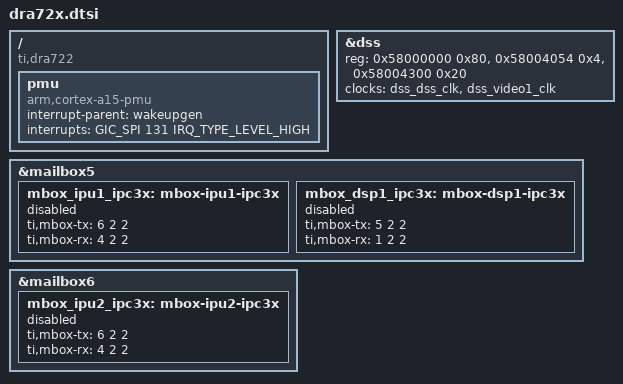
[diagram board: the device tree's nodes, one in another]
// SPDX-License-Identifier: GPL-2.0-only
/*
 * Copyright (C) 2014 Texas Instruments Incorporated - https://www.ti.com/
 *
 * Based on "omap4.dtsi"
 */

#include "dra7.dtsi"

/ {
	compatible = "ti,dra722", "ti,dra72", "ti,dra7";

	pmu {
		compatible = "arm,cortex-a15-pmu";
		interrupt-parent = <&wakeupgen>;
		interrupts = <GIC_SPI 131 IRQ_TYPE_LEVEL_HIGH>;
	};
};

&dss {
	reg = <0x58000000 0x80>,
	      <0x58004054 0x4>,
	      <0x58004300 0x20>;
	reg-names = "dss", "pll1_clkctrl", "pll1";

	clocks = <&dss_dss_clk>,
		 <&dss_video1_clk>;
	clock-names = "fck", "video1_clk";
};

&mailbox5 {
	mbox_ipu1_ipc3x: mbox-ipu1-ipc3x {
		ti,mbox-tx = <6 2 2>;
		ti,mbox-rx = <4 2 2>;
		status = "disabled";
	};
	mbox_dsp1_ipc3x: mbox-dsp1-ipc3x {
		ti,mbox-tx = <5 2 2>;
		ti,mbox-rx = <1 2 2>;
		status = "disabled";
	};
};

&mailbox6 {
	mbox_ipu2_ipc3x: mbox-ipu2-ipc3x {
		ti,mbox-tx = <6 2 2>;
		ti,mbox-rx = <4 2 2>;
		status = "disabled";
	};
};
